# R7FA8M1AH register map
Vendor: Renesas; Series: RA8; File version: 1.2
CPU: CM85 r0p0, little endian, MPU, FPU, VTOR, 4 interrupt priority bits
Registers are 32-bit, read-write, reset 0x0 unless marked. A register's access mark holds for its fields unless they carry their own. Offsets are from the block's base; [hi:lo] are bit positions; 'fields as' and 'values as' point back to an identical list.

## DSILINK (part 3 of 4)
Base 0x40346000
Same registers: DSILINK_NS 0x50346000
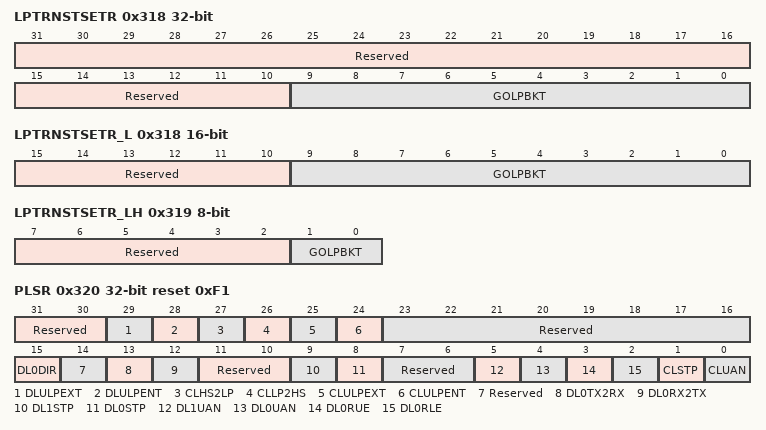
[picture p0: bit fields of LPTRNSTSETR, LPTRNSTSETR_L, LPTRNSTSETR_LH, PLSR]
0x318 LPTRNSTSETR — LP Transition Time Set Register
  [31:10] Reserved — These bits are read as 0000000000000000000000. The write value should be 0000000000000000000000.
  [9:0] GOLPBKT — Go LP and Back Time
0x318 LPTRNSTSETR_L 16-bit (alternate view of LPTRNSTSETR) — LP Transition Time Set Register
  [15:10] Reserved — These bits are read as 000000. The write value should be 000000.
  [9:0] GOLPBKT — Go LP and Back Time
0x318 LPTRNSTSETR_LL 8-bit (alternate view of LPTRNSTSETR) — LP Transition Time Set Register
  [7:0] GOLPBKT — Go LP and Back Time
0x319 LPTRNSTSETR_LH 8-bit (alternate view of LPTRNSTSETR) — LP Transition Time Set Register
  [7:2] Reserved — These bits are read as 000000. The write value should be 000000.
  [1:0] GOLPBKT — Go LP and Back Time
0x320 PLSR ro reset 0xF1 — Physical Lane Status Register
  [31:30] Reserved — These bits are read as 00.
  [29] DLULPEXT — Data Lane ULPS Exit Interrupt Flag
    0=Not detected; 1=Detected
  [28] DLULPENT — Data Lane ULPS Enter Interrupt Flag
    0=Not detected; 1=Detected
  [27] CLHS2LP — Clock Lane HS to LP Transition Interrupt Flag
    0=Not detected; 1=Detected
  [26] CLLP2HS — Clock Lane LP to HS Transition Interrupt Flag
    0=Not detected; 1=Detected
  [25] CLULPEXT — Clock Lane ULPS Exit Interrupt Flag
    0=Not detected; 1=Detected
  [24] CLULPENT — Clock Lane ULPS Enter Interrupt Flag
    0=Not detected; 1=Detected
  [23:16] Reserved — These bits are read as 00000000.
  [15] DL0DIR — Data Lane-0 Direction
    0=Transmitter; 1=Receiver
  [14] Reserved — This bit is read as 0.
  [13] DL0TX2RX — Data Lane-0 TX to RX Transition Interrupt Flag
    0=Not detected; 1=Detected
  [12] DL0RX2TX — Data Lane-0 RX to TX Transition Interrupt Flag
    0=Not detected; 1=Detected
  [11:10] Reserved — These bits are read as 00.
  [9] DL1STP — Data Lane-1 Stop Status
    0=Not in Stop state; 1=In Stop state
  [8] DL0STP — Data Lane-0 Stop Status
    0=Not in Stop state; 1=In Stop state
  [7:6] Reserved — These bits are read as 11.
  [5] DL1UAN — Data Lane-1 UlpsActiveNot Status
    0=In ULP state; 1=Not in ULP state
  [4] DL0UAN — Data Lane-0 UlpsActiveNot Status
    0=In ULP state; 1=Not in ULP state
  [3] DL0RUE — Data Lane-0 RxUlpsEsc Status
    0=Not in Escape Ultra-Low Power (Receive) mode; 1=In Escape Ultra-Low Power (Receive) mode
  [2] DL0RLE — Data Lane-0 RxLpdtEsc Status
    0=Not in Escape Low-Power Data Receive mode; 1=In Escape Low-Power Data Receive mode
  [1] CLSTP — Clock Lane Stop Status
    0=Not in Stop state; 1=In Stop state
  [0] CLUAN — Clock Lane UlpsActiveNot Status
    0=In ULP state; 1=Not in ULP state
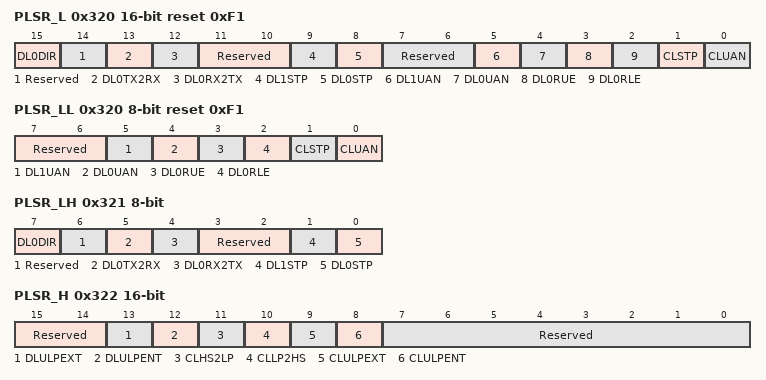
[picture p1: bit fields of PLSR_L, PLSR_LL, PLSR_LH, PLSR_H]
0x320 PLSR_L 16-bit ro reset 0xF1 (alternate view of PLSR) — Physical Lane Status Register
  [15] DL0DIR — Data Lane-0 Direction
    0=Transmitter; 1=Receiver
  [14] Reserved — This bit is read as 0.
  [13] DL0TX2RX — Data Lane-0 TX to RX Transition Interrupt Flag
    0=Not detected; 1=Detected
  [12] DL0RX2TX — Data Lane-0 RX to TX Transition Interrupt Flag
    0=Not detected; 1=Detected
  [11:10] Reserved — These bits are read as 00.
  [9] DL1STP — Data Lane-1 Stop Status
    0=Not in Stop state; 1=In Stop state
  [8] DL0STP — Data Lane-0 Stop Status
    0=Not in Stop state; 1=In Stop state
  [7:6] Reserved — These bits are read as 11.
  [5] DL1UAN — Data Lane-1 UlpsActiveNot Status
    0=In ULP state; 1=Not in ULP state
  [4] DL0UAN — Data Lane-0 UlpsActiveNot Status
    0=In ULP state; 1=Not in ULP state
  [3] DL0RUE — Data Lane-0 RxUlpsEsc Status
    values as PLSR.DL0RUE
  [2] DL0RLE — Data Lane-0 RxLpdtEsc Status
    values as PLSR.DL0RLE
  [1] CLSTP — Clock Lane Stop Status
    0=Not in Stop state; 1=In Stop state
  [0] CLUAN — Clock Lane UlpsActiveNot Status
    0=In ULP state; 1=Not in ULP state
0x320 PLSR_LL 8-bit ro reset 0xF1 (alternate view of PLSR) — Physical Lane Status Register
  [7:6] Reserved — These bits are read as 11.
  [5] DL1UAN — Data Lane-1 UlpsActiveNot Status
    0=In ULP state; 1=Not in ULP state
  [4] DL0UAN — Data Lane-0 UlpsActiveNot Status
    0=In ULP state; 1=Not in ULP state
  [3] DL0RUE — Data Lane-0 RxUlpsEsc Status
    values as PLSR.DL0RUE
  [2] DL0RLE — Data Lane-0 RxLpdtEsc Status
    values as PLSR.DL0RLE
  [1] CLSTP — Clock Lane Stop Status
    0=Not in Stop state; 1=In Stop state
  [0] CLUAN — Clock Lane UlpsActiveNot Status
    0=In ULP state; 1=Not in ULP state
0x321 PLSR_LH 8-bit ro (alternate view of PLSR) — Physical Lane Status Register
  [7] DL0DIR — Data Lane-0 Direction
    0=Transmitter; 1=Receiver
  [6] Reserved — This bit is read as 0.
  [5] DL0TX2RX — Data Lane-0 TX to RX Transition Interrupt Flag
    0=Not detected; 1=Detected
  [4] DL0RX2TX — Data Lane-0 RX to TX Transition Interrupt Flag
    0=Not detected; 1=Detected
  [3:2] Reserved — These bits are read as 00.
  [1] DL1STP — Data Lane-1 Stop Status
    0=Not in Stop state; 1=In Stop state
  [0] DL0STP — Data Lane-0 Stop Status
    0=Not in Stop state; 1=In Stop state
0x322 PLSR_H 16-bit ro (alternate view of PLSR) — Physical Lane Status Register
  [15:14] Reserved — These bits are read as 00.
  [13] DLULPEXT — Data Lane ULPS Exit Interrupt Flag
    0=Not detected; 1=Detected
  [12] DLULPENT — Data Lane ULPS Enter Interrupt Flag
    0=Not detected; 1=Detected
  [11] CLHS2LP — Clock Lane HS to LP Transition Interrupt Flag
    0=Not detected; 1=Detected
  [10] CLLP2HS — Clock Lane LP to HS Transition Interrupt Flag
    0=Not detected; 1=Detected
  [9] CLULPEXT — Clock Lane ULPS Exit Interrupt Flag
    0=Not detected; 1=Detected
  [8] CLULPENT — Clock Lane ULPS Enter Interrupt Flag
    0=Not detected; 1=Detected
  [7:0] Reserved — These bits are read as 00000000.
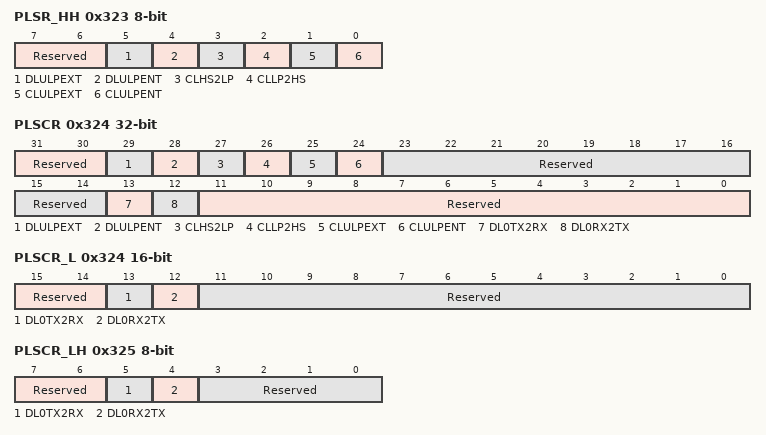
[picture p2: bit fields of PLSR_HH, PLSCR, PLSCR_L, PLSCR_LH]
0x323 PLSR_HH 8-bit ro (alternate view of PLSR) — Physical Lane Status Register
  [7:6] Reserved — These bits are read as 00.
  [5] DLULPEXT — Data Lane ULPS Exit Interrupt Flag
    0=Not detected; 1=Detected
  [4] DLULPENT — Data Lane ULPS Enter Interrupt Flag
    0=Not detected; 1=Detected
  [3] CLHS2LP — Clock Lane HS to LP Transition Interrupt Flag
    0=Not detected; 1=Detected
  [2] CLLP2HS — Clock Lane LP to HS Transition Interrupt Flag
    0=Not detected; 1=Detected
  [1] CLULPEXT — Clock Lane ULPS Exit Interrupt Flag
    0=Not detected; 1=Detected
  [0] CLULPENT — Clock Lane ULPS Enter Interrupt Flag
    0=Not detected; 1=Detected
0x324 PLSCR — Physical Lane Status Clear Register
  [31:30] Reserved — These bits are read as 00. The write value should be 00.
  [29] DLULPEXT write-1-clears read-modifies — Data Lane ULPS Exit Interrupt Flag Clear
    0=No operation; 1=Clear the PLSR.DLULPEXT flag
  [28] DLULPENT write-1-clears read-modifies — Data Lane ULPS Enter Interrupt Flag Clear
    0=No operation; 1=Clear the PLSR.DLULPENT flag
  [27] CLHS2LP write-1-clears read-modifies — Clock Lane HS to LP Transition Interrupt Flag Clear
    0=No operation; 1=Clear the PLSR.CLHS2LP flag
  [26] CLLP2HS write-1-clears read-modifies — Clock Lane LP to HS Transition Interrupt Flag Clear
    0=No operation; 1=Clear the PLSR.CLLP2HS flag
  [25] CLULPEXT write-1-clears read-modifies — Clock Lane ULPS Exit Interrupt Flag Clear
    0=No operation; 1=Clear the PLSR.CLULPEXT flag
  [24] CLULPENT write-1-clears read-modifies — Clock Lane ULPS Enter Interrupt Flag Clear
    0=No operation; 1=Clear the PLSR.CLULPENT flag
  [23:14] Reserved — These bits are read as 0000000000. The write value should be 0000000000.
  [13] DL0TX2RX write-1-clears read-modifies — Data Lane-0 TX to RX Transition Interrupt Flag Clear
    0=No operation; 1=Clear the PLSR.DL0TX2RX flag
  [12] DL0RX2TX write-1-clears read-modifies — Data Lane-0 RX to TX Transition Interrupt Flag Clear
    0=No operation; 1=Clear the PLSR.DL0RX2TX flag
  [11:0] Reserved — These bits are read as 000000000000. The write value should be 000000000000.
0x324 PLSCR_L 16-bit (alternate view of PLSCR) — Physical Lane Status Clear Register
  [15:14] Reserved — These bits are read as 00. The write value should be 00.
  [13] DL0TX2RX write-1-clears read-modifies — Data Lane-0 TX to RX Transition Interrupt Flag Clear
    0=No operation; 1=Clear the PLSR.DL0TX2RX flag
  [12] DL0RX2TX write-1-clears read-modifies — Data Lane-0 RX to TX Transition Interrupt Flag Clear
    0=No operation; 1=Clear the PLSR.DL0RX2TX flag
  [11:0] Reserved — These bits are read as 000000000000. The write value should be 000000000000.
0x325 PLSCR_LH 8-bit (alternate view of PLSCR) — Physical Lane Status Clear Register
  [7:6] Reserved — These bits are read as 00. The write value should be 00.
  [5] DL0TX2RX write-1-clears read-modifies — Data Lane-0 TX to RX Transition Interrupt Flag Clear
    0=No operation; 1=Clear the PLSR.DL0TX2RX flag
  [4] DL0RX2TX write-1-clears read-modifies — Data Lane-0 RX to TX Transition Interrupt Flag Clear
    0=No operation; 1=Clear the PLSR.DL0RX2TX flag
  [3:0] Reserved — These bits are read as 0000. The write value should be 0000.
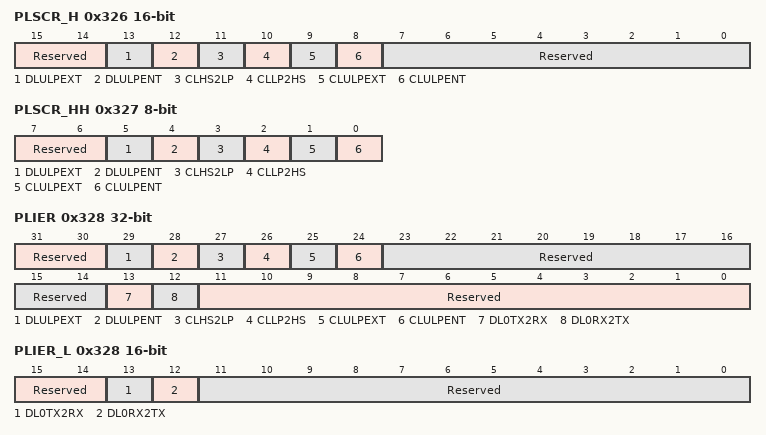
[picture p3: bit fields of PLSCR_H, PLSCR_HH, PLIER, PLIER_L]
0x326 PLSCR_H 16-bit (alternate view of PLSCR) — Physical Lane Status Clear Register
  [15:14] Reserved — These bits are read as 00. The write value should be 00.
  [13] DLULPEXT write-1-clears read-modifies — Data Lane ULPS Exit Interrupt Flag Clear
    0=No operation; 1=Clear the PLSR.DLULPEXT flag
  [12] DLULPENT write-1-clears read-modifies — Data Lane ULPS Enter Interrupt Flag Clear
    0=No operation; 1=Clear the PLSR.DLULPENT flag
  [11] CLHS2LP write-1-clears read-modifies — Clock Lane HS to LP Transition Interrupt Flag Clear
    0=No operation; 1=Clear the PLSR.CLHS2LP flag
  [10] CLLP2HS write-1-clears read-modifies — Clock Lane LP to HS Transition Interrupt Flag Clear
    0=No operation; 1=Clear the PLSR.CLLP2HS flag
  [9] CLULPEXT write-1-clears read-modifies — Clock Lane ULPS Exit Interrupt Flag Clear
    0=No operation; 1=Clear the PLSR.CLULPEXT flag
  [8] CLULPENT write-1-clears read-modifies — Clock Lane ULPS Enter Interrupt Flag Clear
    0=No operation; 1=Clear the PLSR.CLULPENT flag
  [7:0] Reserved — These bits are read as 00000000. The write value should be 00000000.
0x327 PLSCR_HH 8-bit (alternate view of PLSCR) — Physical Lane Status Clear Register
  [7:6] Reserved — These bits are read as 00. The write value should be 00.
  [5] DLULPEXT write-1-clears read-modifies — Data Lane ULPS Exit Interrupt Flag Clear
    0=No operation; 1=Clear the PLSR.DLULPEXT flag
  [4] DLULPENT write-1-clears read-modifies — Data Lane ULPS Enter Interrupt Flag Clear
    0=No operation; 1=Clear the PLSR.DLULPENT flag
  [3] CLHS2LP write-1-clears read-modifies — Clock Lane HS to LP Transition Interrupt Flag Clear
    0=No operation; 1=Clear the PLSR.CLHS2LP flag
  [2] CLLP2HS write-1-clears read-modifies — Clock Lane LP to HS Transition Interrupt Flag Clear
    0=No operation; 1=Clear the PLSR.CLLP2HS flag
  [1] CLULPEXT write-1-clears read-modifies — Clock Lane ULPS Exit Interrupt Flag Clear
    0=No operation; 1=Clear the PLSR.CLULPEXT flag
  [0] CLULPENT write-1-clears read-modifies — Clock Lane ULPS Enter Interrupt Flag Clear
    0=No operation; 1=Clear the PLSR.CLULPENT flag
0x328 PLIER — Physical Lane Interrupt Enable Register
  [31:30] Reserved — These bits are read as 00. The write value should be 00.
  [29] DLULPEXT — Data Lane ULPS Exit Interrupt Enable
    0=Disable; 1=Enable
  [28] DLULPENT — Data Lane ULPS Enter Interrupt Enable
    0=Disable; 1=Enable
  [27] CLHS2LP — Clock Lane HS to LP Transition Interrupt Enable
    0=Disable; 1=Enable
  [26] CLLP2HS — Clock Lane LP to HS Transition Interrupt Enable
    0=Disable; 1=Enable
  [25] CLULPEXT — Clock Lane ULPS Exit Interrupt Enable
    0=Disable; 1=Enable
  [24] CLULPENT — Clock Lane ULPS Enter Interrupt Enable
    0=Disable; 1=Enable
  [23:14] Reserved — These bits are read as 0000000000. The write value should be 0000000000.
  [13] DL0TX2RX — Data Lane-0 TX to RX Transition Interrupt Enable
    0=Disable; 1=Enable
  [12] DL0RX2TX — Data Lane-0 RX to TX Transition Interrupt Enable
    0=Disable; 1=Enable
  [11:0] Reserved — These bits are read as 000000000000. The write value should be 000000000000.
0x328 PLIER_L 16-bit (alternate view of PLIER) — Physical Lane Interrupt Enable Register
  [15:14] Reserved — These bits are read as 00. The write value should be 00.
  [13] DL0TX2RX — Data Lane-0 TX to RX Transition Interrupt Enable
    0=Disable; 1=Enable
  [12] DL0RX2TX — Data Lane-0 RX to TX Transition Interrupt Enable
    0=Disable; 1=Enable
  [11:0] Reserved — These bits are read as 000000000000. The write value should be 000000000000.
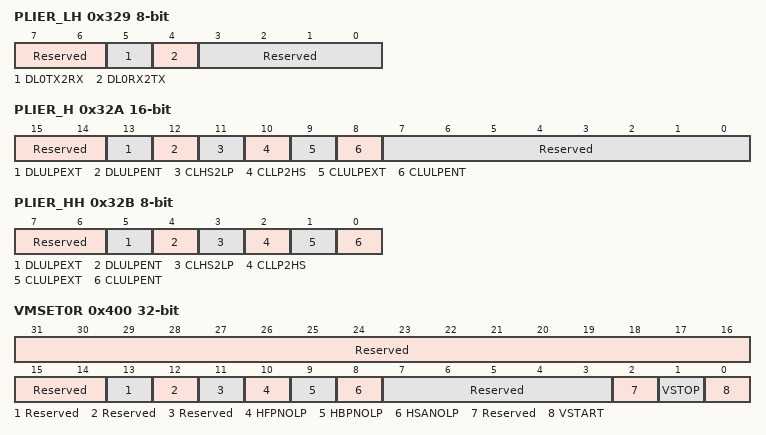
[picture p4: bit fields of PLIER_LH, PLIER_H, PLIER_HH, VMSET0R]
0x329 PLIER_LH 8-bit (alternate view of PLIER) — Physical Lane Interrupt Enable Register
  [7:6] Reserved — These bits are read as 00. The write value should be 00.
  [5] DL0TX2RX — Data Lane-0 TX to RX Transition Interrupt Enable
    0=Disable; 1=Enable
  [4] DL0RX2TX — Data Lane-0 RX to TX Transition Interrupt Enable
    0=Disable; 1=Enable
  [3:0] Reserved — These bits are read as 0000. The write value should be 0000.
0x32A PLIER_H 16-bit (alternate view of PLIER) — Physical Lane Interrupt Enable Register
  [15:14] Reserved — These bits are read as 00. The write value should be 00.
  [13] DLULPEXT — Data Lane ULPS Exit Interrupt Enable
    0=Disable; 1=Enable
  [12] DLULPENT — Data Lane ULPS Enter Interrupt Enable
    0=Disable; 1=Enable
  [11] CLHS2LP — Clock Lane HS to LP Transition Interrupt Enable
    0=Disable; 1=Enable
  [10] CLLP2HS — Clock Lane LP to HS Transition Interrupt Enable
    0=Disable; 1=Enable
  [9] CLULPEXT — Clock Lane ULPS Exit Interrupt Enable
    0=Disable; 1=Enable
  [8] CLULPENT — Clock Lane ULPS Enter Interrupt Enable
    0=Disable; 1=Enable
  [7:0] Reserved — These bits are read as 00000000. The write value should be 00000000.
0x32B PLIER_HH 8-bit (alternate view of PLIER) — Physical Lane Interrupt Enable Register
  [7:6] Reserved — These bits are read as 00. The write value should be 00.
  [5] DLULPEXT — Data Lane ULPS Exit Interrupt Enable
    0=Disable; 1=Enable
  [4] DLULPENT — Data Lane ULPS Enter Interrupt Enable
    0=Disable; 1=Enable
  [3] CLHS2LP — Clock Lane HS to LP Transition Interrupt Enable
    0=Disable; 1=Enable
  [2] CLLP2HS — Clock Lane LP to HS Transition Interrupt Enable
    0=Disable; 1=Enable
  [1] CLULPEXT — Clock Lane ULPS Exit Interrupt Enable
    0=Disable; 1=Enable
  [0] CLULPENT — Clock Lane ULPS Enter Interrupt Enable
    0=Disable; 1=Enable
0x400 VMSET0R — Video Mode Set 0 Register
  [31:14] Reserved — These bits are read as 000000000000000000. The write value should be 000000000000000000.
  [13] Reserved — This bit is read as 0. The write value should be 0.
  [12] Reserved — This bit is read as 0. The write value should be 0.
  [11] Reserved — This bit is read as 0. The write value should be 0.
  [10] HFPNOLP — HFP period No LP
    0=Not suppressing the transition to LP during HFP period; 1=Suppress the transition to LP during HFP period and keep HS
  [9] HBPNOLP — HBP period No LP
    1=Suppress the transition to LP during HBP period and keep HS
  [8] HSANOLP — HSA period No LP
    0=Not suppressing the transition to LP during HSA period; 1=Suppress the transition to LP during HSA period and keep HS
  [7:3] Reserved — These bits are read as 00000. The write value should be 00000.
  [2] Reserved — This bit is read as 0. The write value should be 0.
  [1] VSTOP wo — Video Mode Operation Stop
    0=No operation; 1=Stop Video mode operation
  [0] VSTART wo — Video Mode Operation Start
    0=No operation; 1=Start Video mode operation
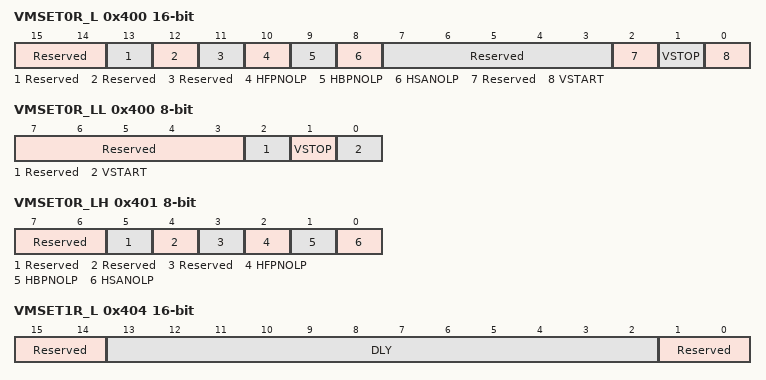
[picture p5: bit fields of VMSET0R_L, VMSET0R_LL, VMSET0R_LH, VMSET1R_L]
0x400 VMSET0R_L 16-bit (alternate view of VMSET0R) — Video Mode Set 0 Register
  [15:14] Reserved — These bits are read as 00. The write value should be 00.
  [13] Reserved — This bit is read as 0. The write value should be 0.
  [12] Reserved — This bit is read as 0. The write value should be 0.
  [11] Reserved — This bit is read as 0. The write value should be 0.
  [10] HFPNOLP — HFP period No LP
    values as VMSET0R.HFPNOLP
  [9] HBPNOLP — HBP period No LP
    values as VMSET0R.HBPNOLP
  [8] HSANOLP — HSA period No LP
    values as VMSET0R.HSANOLP
  [7:3] Reserved — These bits are read as 00000. The write value should be 00000.
  [2] Reserved — This bit is read as 0. The write value should be 0.
  [1] VSTOP wo — Video Mode Operation Stop
    0=No operation; 1=Stop Video mode operation
  [0] VSTART wo — Video Mode Operation Start
    0=No operation; 1=Start Video mode operation
0x400 VMSET0R_LL 8-bit (alternate view of VMSET0R) — Video Mode Set 0 Register
  [7:3] Reserved — These bits are read as 00000. The write value should be 00000.
  [2] Reserved — This bit is read as 0. The write value should be 0.
  [1] VSTOP wo — Video Mode Operation Stop
    0=No operation; 1=Stop Video mode operation
  [0] VSTART wo — Video Mode Operation Start
    0=No operation; 1=Start Video mode operation
0x401 VMSET0R_LH 8-bit (alternate view of VMSET0R) — Video Mode Set 0 Register
  [7:6] Reserved — These bits are read as 00. The write value should be 00.
  [5] Reserved — This bit is read as 0. The write value should be 0.
  [4] Reserved — This bit is read as 0. The write value should be 0.
  [3] Reserved — This bit is read as 0. The write value should be 0.
  [2] HFPNOLP — HFP period No LP
    values as VMSET0R.HFPNOLP
  [1] HBPNOLP — HBP period No LP
    values as VMSET0R.HBPNOLP
  [0] HSANOLP — HSA period No LP
    values as VMSET0R.HSANOLP
0x404 VMSET1R_L 16-bit (alternate view of VMSET1R) — Video Mode Set 1 Register
  [15:14] Reserved — These bits are read as 00. The write value should be 00.
  [13:2] DLY — Delay Value
  [1:0] Reserved — These bits are read as 00. The write value should be 00.
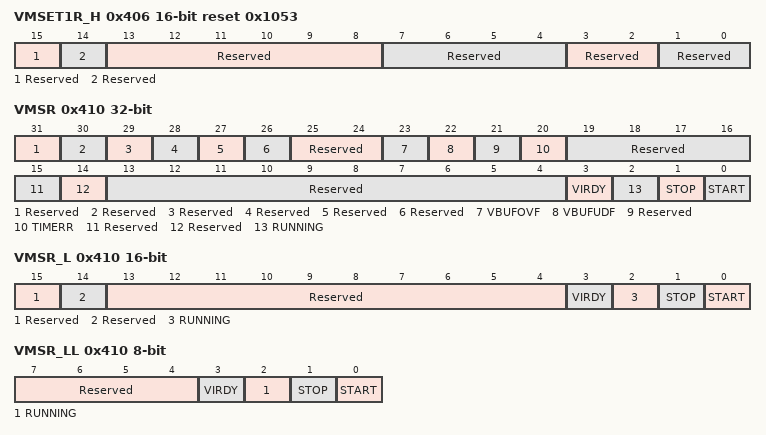
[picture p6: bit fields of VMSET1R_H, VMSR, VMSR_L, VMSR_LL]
0x406 VMSET1R_H 16-bit ro reset 0x1053 (alternate view of VMSET1R) — Video Mode Set 1 Register
  [15] Reserved — This bit is read as 0.
  [14] Reserved — This bit is read as 0.
  [13:8] Reserved — These bits are read as 010000.
  [7:4] Reserved — These bits are read as 0101.
  [3:2] Reserved — These bits are read as 00.
  [1:0] Reserved — These bits are read as 11.
0x410 VMSR ro — Video Mode Status Register
  [31] Reserved — This bit is read as 0.
  [30] Reserved — This bit is read as 0.
  [29] Reserved — This bit is read as 0.
  [28] Reserved — This bit is read as 0.
  [27] Reserved — This bit is read as 0.
  [26] Reserved — This bit is read as 0.
  [25:24] Reserved — These bits are read as 00.
  [23] VBUFOVF — Video Buffer Overflow Error Interrupt Flag
    0=Data overflow is not occurred; 1=Data overflow is occurred in the video buffer
  [22] VBUFUDF — Video Buffer Underflow Error Interrupt Flag
    0=Data underflow is not occurred; 1=Data underflow is occurred in the video buffer
  [21] Reserved — This bit is read as 0.
  [20] TIMERR — Timing Error Interrupt Flag
    0=Timing error is not occurred; 1=Timing error is occurred during the video mode operation
  [19:15] Reserved — These bits are read as 00000.
  [14] Reserved — This bit is read as 0.
  [13:4] Reserved — These bits are read as 0000000000.
  [3] VIRDY — Video Mode Operation Ready Interrupt Flag
    0=Video mode operation is not ready; 1=Video mode operation is ready
  [2] RUNNING — Video Mode Operation Running Status
    0=Video mode operation is stopped; 1=Video mode operation is running
  [1] STOP — Video Mode Operation Stop Interrupt Flag
    0=Video mode operation has not stopped; 1=Video mode operation has stopped
  [0] START — Video Mode Operation Start Interrupt Flag
    0=Video mode operation has not started; 1=Video mode operation has started
0x410 VMSR_L 16-bit ro (alternate view of VMSR) — Video Mode Status Register
  [15] Reserved — This bit is read as 0.
  [14] Reserved — This bit is read as 0.
  [13:4] Reserved — These bits are read as 0000000000.
  [3] VIRDY — Video Mode Operation Ready Interrupt Flag
    values as VMSR.VIRDY
  [2] RUNNING — Video Mode Operation Running Status
    values as VMSR.RUNNING
  [1] STOP — Video Mode Operation Stop Interrupt Flag
    values as VMSR.STOP
  [0] START — Video Mode Operation Start Interrupt Flag
    values as VMSR.START
0x410 VMSR_LL 8-bit ro (alternate view of VMSR) — Video Mode Status Register
  [7:4] Reserved — These bits are read as 0000.
  [3] VIRDY — Video Mode Operation Ready Interrupt Flag
    values as VMSR.VIRDY
  [2] RUNNING — Video Mode Operation Running Status
    values as VMSR.RUNNING
  [1] STOP — Video Mode Operation Stop Interrupt Flag
    values as VMSR.STOP
  [0] START — Video Mode Operation Start Interrupt Flag
    values as VMSR.START
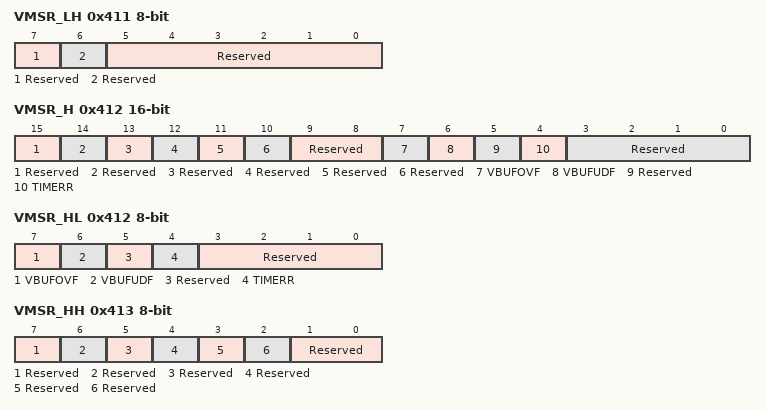
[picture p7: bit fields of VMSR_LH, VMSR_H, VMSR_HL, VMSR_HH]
0x411 VMSR_LH 8-bit ro (alternate view of VMSR) — Video Mode Status Register
  [7] Reserved — This bit is read as 0.
  [6] Reserved — This bit is read as 0.
  [5:0] Reserved — These bits are read as 000000.
0x412 VMSR_H 16-bit ro (alternate view of VMSR) — Video Mode Status Register
  [15] Reserved — This bit is read as 0.
  [14] Reserved — This bit is read as 0.
  [13] Reserved — This bit is read as 0.
  [12] Reserved — This bit is read as 0.
  [11] Reserved — This bit is read as 0.
  [10] Reserved — This bit is read as 0.
  [9:8] Reserved — These bits are read as 00.
  [7] VBUFOVF — Video Buffer Overflow Error Interrupt Flag
    values as VMSR.VBUFOVF
  [6] VBUFUDF — Video Buffer Underflow Error Interrupt Flag
    values as VMSR.VBUFUDF
  [5] Reserved — This bit is read as 0.
  [4] TIMERR — Timing Error Interrupt Flag
    values as VMSR.TIMERR
  [3:0] Reserved — These bits are read as 0000.
0x412 VMSR_HL 8-bit ro (alternate view of VMSR) — Video Mode Status Register
  [7] VBUFOVF — Video Buffer Overflow Error Interrupt Flag
    values as VMSR.VBUFOVF
  [6] VBUFUDF — Video Buffer Underflow Error Interrupt Flag
    values as VMSR.VBUFUDF
  [5] Reserved — This bit is read as 0.
  [4] TIMERR — Timing Error Interrupt Flag
    values as VMSR.TIMERR
  [3:0] Reserved — These bits are read as 0000.
0x413 VMSR_HH 8-bit ro (alternate view of VMSR) — Video Mode Status Register
  [7] Reserved — This bit is read as 0.
  [6] Reserved — This bit is read as 0.
  [5] Reserved — This bit is read as 0.
  [4] Reserved — This bit is read as 0.
  [3] Reserved — This bit is read as 0.
  [2] Reserved — This bit is read as 0.
  [1:0] Reserved — These bits are read as 00.
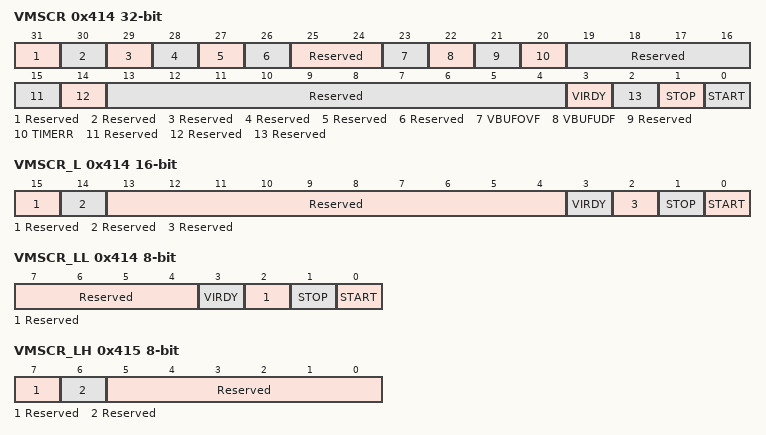
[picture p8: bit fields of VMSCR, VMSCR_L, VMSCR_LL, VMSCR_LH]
0x414 VMSCR — Video Mode Status Clear Register
  [31] Reserved — This bit is read as 0. The write value should be 0.
  [30] Reserved — This bit is read as 0. The write value should be 0.
  [29] Reserved — This bit is read as 0. The write value should be 0.
  [28] Reserved — This bit is read as 0. The write value should be 0.
  [27] Reserved — This bit is read as 0. The write value should be 0.
  [26] Reserved — This bit is read as 0. The write value should be 0.
  [25:24] Reserved — These bits are read as 00. The write value should be 00.
  [23] VBUFOVF write-1-clears read-modifies — Video Buffer Overflow Error Interrupt Flag Clear
    0=No operation; 1=Clear the VMSR.VBUFOVF flag
  [22] VBUFUDF write-1-clears read-modifies — Video Buffer Underflow Error Interrupt Flag Clear
    0=No operation; 1=Clear the VMSR.VBUFUDF flag
  [21] Reserved — This bit is read as 0. The write value should be 0.
  [20] TIMERR write-1-clears read-modifies — Timing Error Interrupt Flag Clear
    0=No operation; 1=Clear the VMSR.TIMERR flag
  [19:15] Reserved — These bits are read as 00000. The write value should be 00000.
  [14] Reserved — This bit is read as 0. The write value should be 0.
  [13:4] Reserved — These bits are read as 0000000000. The write value should be 0000000000.
  [3] VIRDY write-1-clears read-modifies — Video Mode Operation Ready Interrupt Flag Clear
    0=No operation; 1=Clear the VMSR.VIRDY flag
  [2] Reserved — This bit is read as 0. The write value should be 0.
  [1] STOP write-1-clears read-modifies — Video Mode Operation Stop Interrupt Flag Clear
    0=No operation; 1=Clear the VMSR.STOP flag
  [0] START write-1-clears read-modifies — Video Mode Operation Start Interrupt Flag Clear
    0=No operation; 1=Clear the VMSR.START flag
0x414 VMSCR_L 16-bit (alternate view of VMSCR) — Video Mode Status Clear Register
  [15] Reserved — This bit is read as 0. The write value should be 0.
  [14] Reserved — This bit is read as 0. The write value should be 0.
  [13:4] Reserved — These bits are read as 0000000000. The write value should be 0000000000.
  [3] VIRDY write-1-clears read-modifies — Video Mode Operation Ready Interrupt Flag Clear
    0=No operation; 1=Clear the VMSR.VIRDY flag
  [2] Reserved — This bit is read as 0. The write value should be 0.
  [1] STOP write-1-clears read-modifies — Video Mode Operation Stop Interrupt Flag Clear
    0=No operation; 1=Clear the VMSR.STOP flag
  [0] START write-1-clears read-modifies — Video Mode Operation Start Interrupt Flag Clear
    0=No operation; 1=Clear the VMSR.START flag
0x414 VMSCR_LL 8-bit (alternate view of VMSCR) — Video Mode Status Clear Register
  [7:4] Reserved — These bits are read as 0000. The write value should be 0000.
  [3] VIRDY write-1-clears read-modifies — Video Mode Operation Ready Interrupt Flag Clear
    0=No operation; 1=Clear the VMSR.VIRDY flag
  [2] Reserved — This bit is read as 0. The write value should be 0.
  [1] STOP write-1-clears read-modifies — Video Mode Operation Stop Interrupt Flag Clear
    0=No operation; 1=Clear the VMSR.STOP flag
  [0] START write-1-clears read-modifies — Video Mode Operation Start Interrupt Flag Clear
    0=No operation; 1=Clear the VMSR.START flag
0x415 VMSCR_LH 8-bit (alternate view of VMSCR) — Video Mode Status Clear Register
  [7] Reserved — This bit is read as 0. The write value should be 0.
  [6] Reserved — This bit is read as 0. The write value should be 0.
  [5:0] Reserved — These bits are read as 000000. The write value should be 000000.
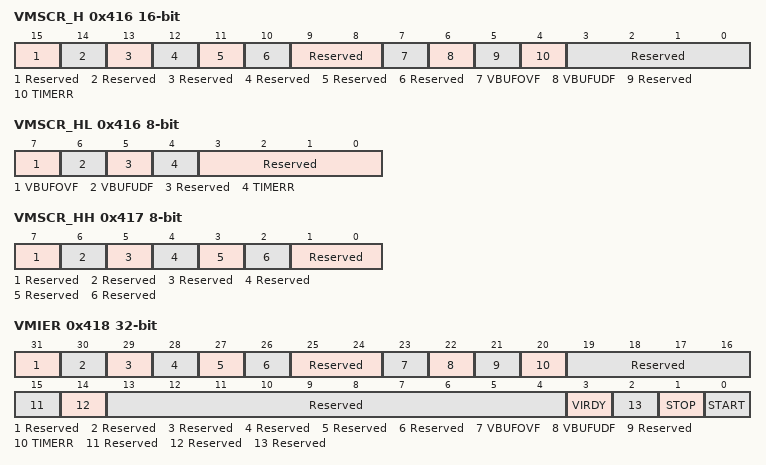
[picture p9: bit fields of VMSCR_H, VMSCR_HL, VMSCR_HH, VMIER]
0x416 VMSCR_H 16-bit (alternate view of VMSCR) — Video Mode Status Clear Register
  [15] Reserved — This bit is read as 0. The write value should be 0.
  [14] Reserved — This bit is read as 0. The write value should be 0.
  [13] Reserved — This bit is read as 0. The write value should be 0.
  [12] Reserved — This bit is read as 0. The write value should be 0.
  [11] Reserved — This bit is read as 0. The write value should be 0.
  [10] Reserved — This bit is read as 0. The write value should be 0.
  [9:8] Reserved — These bits are read as 00. The write value should be 00.
  [7] VBUFOVF write-1-clears read-modifies — Video Buffer Overflow Error Interrupt Flag Clear
    0=No operation; 1=Clear the VMSR.VBUFOVF flag
  [6] VBUFUDF write-1-clears read-modifies — Video Buffer Underflow Error Interrupt Flag Clear
    0=No operation; 1=Clear the VMSR.VBUFUDF flag
  [5] Reserved — This bit is read as 0. The write value should be 0.
  [4] TIMERR write-1-clears read-modifies — Timing Error Interrupt Flag Clear
    0=No operation; 1=Clear the VMSR.TIMERR flag
  [3:0] Reserved — These bits are read as 0000. The write value should be 0000.
0x416 VMSCR_HL 8-bit (alternate view of VMSCR) — Video Mode Status Clear Register
  [7] VBUFOVF write-1-clears read-modifies — Video Buffer Overflow Error Interrupt Flag Clear
    0=No operation; 1=Clear the VMSR.VBUFOVF flag
  [6] VBUFUDF write-1-clears read-modifies — Video Buffer Underflow Error Interrupt Flag Clear
    0=No operation; 1=Clear the VMSR.VBUFUDF flag
  [5] Reserved — This bit is read as 0. The write value should be 0.
  [4] TIMERR write-1-clears read-modifies — Timing Error Interrupt Flag Clear
    0=No operation; 1=Clear the VMSR.TIMERR flag
  [3:0] Reserved — These bits are read as 0000. The write value should be 0000.
0x417 VMSCR_HH 8-bit (alternate view of VMSCR) — Video Mode Status Clear Register
  [7] Reserved — This bit is read as 0. The write value should be 0.
  [6] Reserved — This bit is read as 0. The write value should be 0.
  [5] Reserved — This bit is read as 0. The write value should be 0.
  [4] Reserved — This bit is read as 0. The write value should be 0.
  [3] Reserved — This bit is read as 0. The write value should be 0.
  [2] Reserved — This bit is read as 0. The write value should be 0.
  [1:0] Reserved — These bits are read as 00. The write value should be 00.
0x418 VMIER — Video Mode Interrupt Enable Register
  [31] Reserved — This bit is read as 0. The write value should be 0.
  [30] Reserved — This bit is read as 0. The write value should be 0.
  [29] Reserved — This bit is read as 0. The write value should be 0.
  [28] Reserved — This bit is read as 0. The write value should be 0.
  [27] Reserved — This bit is read as 0. The write value should be 0.
  [26] Reserved — This bit is read as 0. The write value should be 0.
  [25:24] Reserved — These bits are read as 00. The write value should be 00.
  [23] VBUFOVF — Video Buffer Overflow Error Interrupt Enable
    0=Disable; 1=Enable
  [22] VBUFUDF — Video Buffer Underflow Error Interrupt Enable
    0=Disable; 1=Enable
  [21] Reserved — This bit is read as 0. The write value should be 0.
  [20] TIMERR — Timing Error Interrupt Enable
    0=Disable; 1=Enable
  [19:15] Reserved — These bits are read as 00000. The write value should be 00000.
  [14] Reserved — This bit is read as 0. The write value should be 0.
  [13:4] Reserved — These bits are read as 0000000000. The write value should be 0000000000.
  [3] VIRDY — Video Mode Operation Ready Interrupt Enable
    0=Disable; 1=Enable
  [2] Reserved — This bit is read as 0. The write value should be 0.
  [1] STOP — Video Mode Operation Stop Interrupt Enable
    0=Disable; 1=Enable
  [0] START — Video Mode Operation Start Interrupt Enable
    0=Disable; 1=Enable
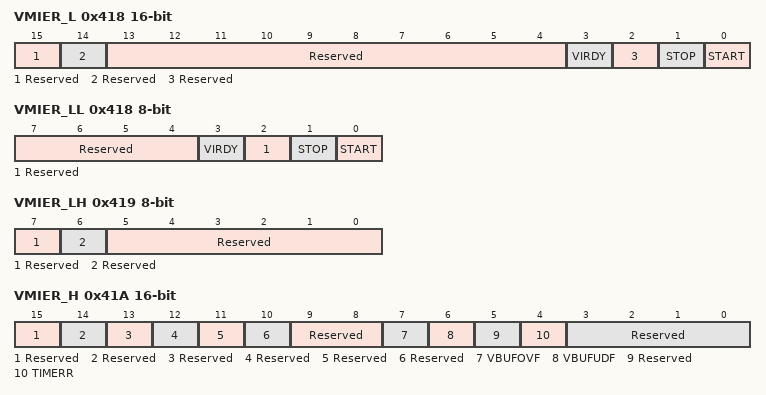
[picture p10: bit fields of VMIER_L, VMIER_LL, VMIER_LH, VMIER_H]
0x418 VMIER_L 16-bit (alternate view of VMIER) — Video Mode Interrupt Enable Register
  [15] Reserved — This bit is read as 0. The write value should be 0.
  [14] Reserved — This bit is read as 0. The write value should be 0.
  [13:4] Reserved — These bits are read as 0000000000. The write value should be 0000000000.
  [3] VIRDY — Video Mode Operation Ready Interrupt Enable
    0=Disable; 1=Enable
  [2] Reserved — This bit is read as 0. The write value should be 0.
  [1] STOP — Video Mode Operation Stop Interrupt Enable
    0=Disable; 1=Enable
  [0] START — Video Mode Operation Start Interrupt Enable
    0=Disable; 1=Enable
0x418 VMIER_LL 8-bit (alternate view of VMIER) — Video Mode Interrupt Enable Register
  [7:4] Reserved — These bits are read as 0000. The write value should be 0000.
  [3] VIRDY — Video Mode Operation Ready Interrupt Enable
    0=Disable; 1=Enable
  [2] Reserved — This bit is read as 0. The write value should be 0.
  [1] STOP — Video Mode Operation Stop Interrupt Enable
    0=Disable; 1=Enable
  [0] START — Video Mode Operation Start Interrupt Enable
    0=Disable; 1=Enable
0x419 VMIER_LH 8-bit (alternate view of VMIER) — Video Mode Interrupt Enable Register
  fields as VMSCR_LH
0x41A VMIER_H 16-bit (alternate view of VMIER) — Video Mode Interrupt Enable Register
  [15] Reserved — This bit is read as 0. The write value should be 0.
  [14] Reserved — This bit is read as 0. The write value should be 0.
  [13] Reserved — This bit is read as 0. The write value should be 0.
  [12] Reserved — This bit is read as 0. The write value should be 0.
  [11] Reserved — This bit is read as 0. The write value should be 0.
  [10] Reserved — This bit is read as 0. The write value should be 0.
  [9:8] Reserved — These bits are read as 00. The write value should be 00.
  [7] VBUFOVF — Video Buffer Overflow Error Interrupt Enable
    0=Disable; 1=Enable
  [6] VBUFUDF — Video Buffer Underflow Error Interrupt Enable
    0=Disable; 1=Enable
  [5] Reserved — This bit is read as 0. The write value should be 0.
  [4] TIMERR — Timing Error Interrupt Enable
    0=Disable; 1=Enable
  [3:0] Reserved — These bits are read as 0000. The write value should be 0000.
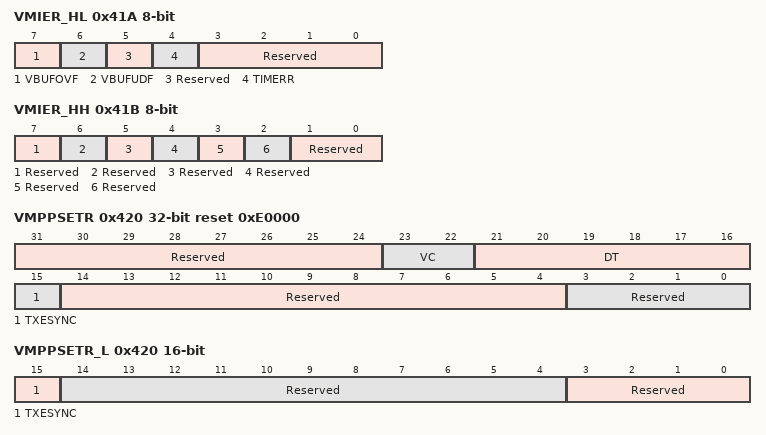
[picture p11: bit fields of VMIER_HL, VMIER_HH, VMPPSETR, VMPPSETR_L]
0x41A VMIER_HL 8-bit (alternate view of VMIER) — Video Mode Interrupt Enable Register
  [7] VBUFOVF — Video Buffer Overflow Error Interrupt Enable
    0=Disable; 1=Enable
  [6] VBUFUDF — Video Buffer Underflow Error Interrupt Enable
    0=Disable; 1=Enable
  [5] Reserved — This bit is read as 0. The write value should be 0.
  [4] TIMERR — Timing Error Interrupt Enable
    0=Disable; 1=Enable
  [3:0] Reserved — These bits are read as 0000. The write value should be 0000.
0x41B VMIER_HH 8-bit (alternate view of VMIER) — Video Mode Interrupt Enable Register
  fields as VMSCR_HH
0x420 VMPPSETR reset 0xE0000 — Video Mode Pixel Packet Set Register
  [31:24] Reserved — These bits are read as 00000000. The write value should be 00000000.
  [23:22] VC — Video Mode Virtual Channel
  [21:16] DT — Video Mode Data Type
    14=Packed Pixel Stream, 16 bit RGB; 30=Packed Pixel Stream, 18 bit RGB; 62=Packed Pixel Stream, 24 bit RGB
  [15] TXESYNC — Transmit End of Sync Pulse
    0=HSE and VSE are not transmitted; 1=HSE and VSE are transmitted
  [14:4] Reserved — These bits are read as 00000000000. The write value should be 00000000000.
  [3:0] Reserved — These bits are read as 0000. The write value should be 0000.
0x420 VMPPSETR_L 16-bit (alternate view of VMPPSETR) — Video Mode Pixel Packet Set Register
  [15] TXESYNC — Transmit End of Sync Pulse
    values as VMPPSETR.TXESYNC
  [14:4] Reserved — These bits are read as 00000000000. The write value should be 00000000000.
  [3:0] Reserved — These bits are read as 0000. The write value should be 0000.
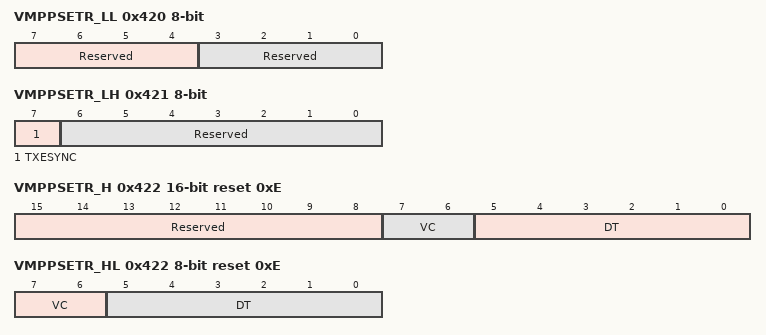
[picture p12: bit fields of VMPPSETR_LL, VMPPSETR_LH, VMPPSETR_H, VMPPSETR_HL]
0x420 VMPPSETR_LL 8-bit (alternate view of VMPPSETR) — Video Mode Pixel Packet Set Register
  [7:4] Reserved — These bits are read as 0000. The write value should be 0000.
  [3:0] Reserved — These bits are read as 0000. The write value should be 0000.
0x421 VMPPSETR_LH 8-bit (alternate view of VMPPSETR) — Video Mode Pixel Packet Set Register
  [7] TXESYNC — Transmit End of Sync Pulse
    values as VMPPSETR.TXESYNC
  [6:0] Reserved — These bits are read as 0000000. The write value should be 0000000.
0x422 VMPPSETR_H 16-bit reset 0xE (alternate view of VMPPSETR) — Video Mode Pixel Packet Set Register
  [15:8] Reserved — These bits are read as 00000000. The write value should be 00000000.
  [7:6] VC — Video Mode Virtual Channel
  [5:0] DT — Video Mode Data Type
    values as VMPPSETR.DT
0x422 VMPPSETR_HL 8-bit reset 0xE (alternate view of VMPPSETR) — Video Mode Pixel Packet Set Register
  [7:6] VC — Video Mode Virtual Channel
  [5:0] DT — Video Mode Data Type
    values as VMPPSETR.DT
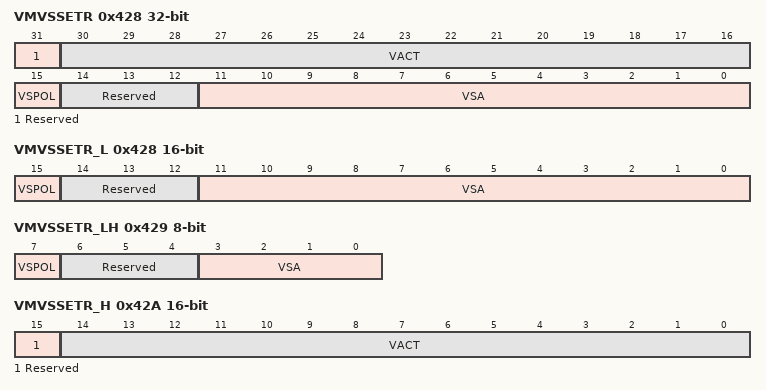
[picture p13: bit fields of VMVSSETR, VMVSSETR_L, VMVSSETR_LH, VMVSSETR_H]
0x428 VMVSSETR — Video Mode Vertical Size Set Register
  [31] Reserved — This bit is read as 0. The write value should be 0.
  [30:16] VACT — Vertical Active Lines
  [15] VSPOL — VSYNC Polarity
    0=High Active; 1=Low Active
  [14:12] Reserved — These bits are read as 000. The write value should be 000.
  [11:0] VSA — VSA Lines
0x428 VMVSSETR_L 16-bit (alternate view of VMVSSETR) — Video Mode Vertical Size Set Register
  [15] VSPOL — VSYNC Polarity
    0=High Active; 1=Low Active
  [14:12] Reserved — These bits are read as 000. The write value should be 000.
  [11:0] VSA — VSA Lines
0x428 VMVSSETR_LL 8-bit (alternate view of VMVSSETR) — Video Mode Vertical Size Set Register
  [7:0] VSA — VSA Lines
0x429 VMVSSETR_LH 8-bit (alternate view of VMVSSETR) — Video Mode Vertical Size Set Register
  [7] VSPOL — VSYNC Polarity
    0=High Active; 1=Low Active
  [6:4] Reserved — These bits are read as 000. The write value should be 000.
  [3:0] VSA — VSA Lines
0x42A VMVSSETR_H 16-bit (alternate view of VMVSSETR) — Video Mode Vertical Size Set Register
  [15] Reserved — This bit is read as 0. The write value should be 0.
  [14:0] VACT — Vertical Active Lines
0x42A VMVSSETR_HL 8-bit (alternate view of VMVSSETR) — Video Mode Vertical Size Set Register
  [7:0] VACT — Vertical Active Lines
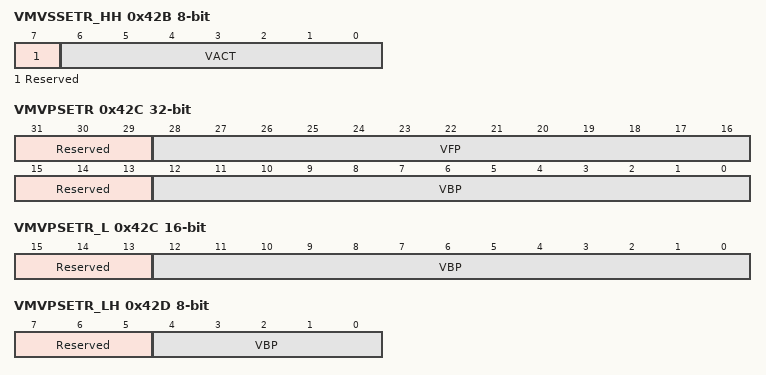
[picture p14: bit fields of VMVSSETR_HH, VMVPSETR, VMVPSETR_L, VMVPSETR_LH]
0x42B VMVSSETR_HH 8-bit (alternate view of VMVSSETR) — Video Mode Vertical Size Set Register
  [7] Reserved — This bit is read as 0. The write value should be 0.
  [6:0] VACT — Vertical Active Lines
0x42C VMVPSETR — Video Mode Vertical Porch Set Register
  [31:29] Reserved — These bits are read as 000. The write value should be 000.
  [28:16] VFP — VFP Lines
  [15:13] Reserved — These bits are read as 000. The write value should be 000.
  [12:0] VBP — VBP Lines
0x42C VMVPSETR_L 16-bit (alternate view of VMVPSETR) — Video Mode Vertical Porch Set Register
  [15:13] Reserved — These bits are read as 000. The write value should be 000.
  [12:0] VBP — VBP Lines
0x42C VMVPSETR_LL 8-bit (alternate view of VMVPSETR) — Video Mode Vertical Porch Set Register
  [7:0] VBP — VBP Lines
0x42D VMVPSETR_LH 8-bit (alternate view of VMVPSETR) — Video Mode Vertical Porch Set Register
  [7:5] Reserved — These bits are read as 000. The write value should be 000.
  [4:0] VBP — VBP Lines
0x42E VMVPSETR_H 16-bit (alternate view of VMVPSETR) — Video Mode Vertical Porch Set Register
  [15:13] Reserved — These bits are read as 000. The write value should be 000.
  [12:0] VFP — VFP Lines
0x42E VMVPSETR_HL 8-bit (alternate view of VMVPSETR) — Video Mode Vertical Porch Set Register
  [7:0] VFP — VFP Lines
